# SPC1169 register map
File version: 2022071043481212
CPU: cm4 r1p0, little endian, no MPU, FPU, 4 interrupt priority bits
Registers are 32-bit, read-write, reset 0x0 unless marked. A register's access mark holds for its fields unless they carry their own. Offsets are from the block's base; [hi:lo] are bit positions; {n}, {i} and the like mark numbered series; 'fields as' and 'values as' point back to an identical list.

## ECAP
Base 0x40003400
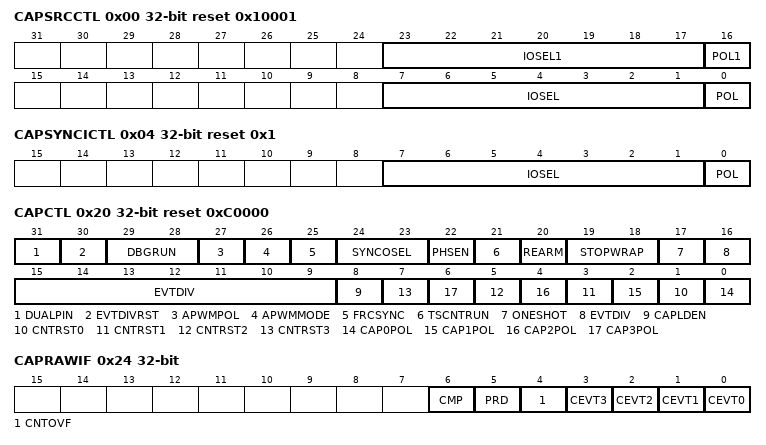
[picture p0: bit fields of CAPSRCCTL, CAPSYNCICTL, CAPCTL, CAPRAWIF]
0x00 CAPSRCCTL reset 0x10001 — Capture Source Input Control Register
  [23:17] IOSEL1 — GPIO number to be selected as 2nd capture input in dual pin mode
  [16] POL1 — Source input polarity for the 2nd pin in dual pin mode
    0=ACTIVE_LOW; 1=ACTIVE_HIGH
  [7:1] IOSEL — GPIO number to be selected as capture input
  [0] POL — Source input polarity
    0=ACTIVE_LOW; 1=ACTIVE_HIGH
0x04 CAPSYNCICTL reset 0x1 — Capture Synchronization Source Input Control Register
  [7:1] IOSEL — GPIO number to be selected as sync input
  [0] POL — Source input polarity
    0=ACTIVE_LOW; 1=ACTIVE_HIGH
0x08 CAPTSCNT — Time-Stamp Counter Register
  [31:0] VAL — Active 32-bit counter register that is used as the capture time-base.
0x0C CAPCNTPHS — Counter Phase Offset Value Register
  [31:0] VAL — Counter phase value register that can be programmed for phase lag/lead.
0x10 CAP0 — Capture Register 0
  [31:0] VAL — In capture mode -This register is loaded from time-stamp counter (CAPTSCNT) upon a capture event 0. . In APWM mode -Writting to this register set the active value of PRD, and also update CAP2 with the same value. This emulates the immediate mode. - Upon CAPTSCNT=PRD (CAP0), this register is updated as CAP2. This emulates the shadow mode.
0x14 CAP1 — Capture Register 1
  [31:0] VAL — In capture mode -This register is loaded from time-stamp counter (CAPTSCNT) upon a capture event 1. . In APWM mode -Writting to this register set the active value of CMP, and also update CAP3 with the same value. This emulates the immediate mode. - Upon CAPTSCNT=PRD (CAP0), this register is updated as CAP3. This emulates the shadow mode.
0x18 CAP2 — Capture Register 2
  [31:0] VAL — In capture mode -This register is loaded from time-stamp counter (CAPTSCNT) upon a capture event 2. . In APWM mode -Writting to this register set the shadow value of PRD. Upon CAPTSCNT=PRD (CAP0), CAP0 will be updated to the value of this register. This emulates the shadow mode.
0x1C CAP3 — Capture Register 3
  [31:0] VAL — In capture mode -This register is loaded from time-stamp counter (CAPTSCNT) upon a capture event 3. . In APWM mode -Writting to this register set the shadow value of CMP. Upon CAPTSCNT=PRD (CAP0), CAP1 will be updated to the value of this register. This emulates the shadow mode.
0x20 CAPCTL reset 0xC0000 — Capture Control Register
  [31] DUALPIN — Dual pin capture mode
    0=DISABLE (CAP0 ~ CAP3 are used for capture the single pin); 1=ENABLE (Use CAP0/CAP2 to capture one pin and CAP1/CAP3 to capture the other)
  [30] EVTDIVRST — Event divider reset
    0=NO_EFFECT (Write 0 has no effect and always reads back 0); 1=RESET (Write 1 resets the event divider. This bit is self-cleared)
  [29:28] DBGRUN — ECAP counter behaviour when CPU is halted. Note: Debug operation and CPU fault exceptions both can cause CPU halted.
    0=STOP_IMMEDIATELY (Counter stops immediately when CPU is halted); 1=STOP_AT_ZERO (Counter runs until 0 when CPU is halted); 2=KEEP_RUNNING (Counter is unaffected when CPU is halted)
  [27] APWMPOL — APWM output polarity select. This is applicable only in APWM operating mode.
    0=ACTIVE_LOW (Output is active low (i.e., CMP defines duration for output low)); 1=ACTIVE_HIGH (Output is active high (i.e., CMP defines duration for output high))
  [26] APWMMODE — CAP/APWM operating mode select
    0=CAPTURE_MODE (ECAP module operates in capture mode. This mode forces the following configuration: - Inhibits counter reset via CNT = PRD event - Inhibits shadow load on CAP0 and CAP1 registers - Permits user to enable CAP0-3 register load - CAPx/APWMx pin operates as a capture input); 1=APWM_MODE (ECAP module operates in APWM mode. This mode forces the following configuration: - Resets counter on CNT = PRD event (period boundary - Permits shadow loading on CAP0 and CAP1 registers - Disables loading of time-stamps into CAP0-3 registers - CAPx/APWMx pin operates as a APWM output)
  [25] FRCSYNC — Software-forced counter synchronizing.
    0=NO_EFFECT (Write 0 has no effect and always reads back 0); 1=FORCE (Write 1 forces a sync event. This bit is self-cleared.)
  [24:23] SYNCOSEL — Sync-Out Select
    1=DISABLE_SYNC_OUT (Disable sync out signal); 2=SYNC_IN (Select sync-in event to be the sync-out signal (pass through)); 3=CNT_EQU_PRD (Select CNT = PRD event to be the sync-out signal)
  [22] PHSEN — Phase synchronization enable
    0=DISABLE (Disable synchronization); 1=ENABLE (Enable counter (CAPTSCNT) to be loaded from CAPCNTPHS register upon either a SYNCI signal or a S/W force event)
  [21] TSCNTRUN — Time stamp counter run/stop control
    0=STOP_COUNTER (Stop counting); 1=START_COUNTER (Free running)
  [20] REARM — One-shot re-arming control.
    0=NO_EFFECT (Write 0 has no effect and always reads back 0); 1=FORCE (Write 1 forces events below. This bit is self-cleared. - Resets the MOD4 counter to zero - Unfreezes the MOD4 counter - Enables capture register loads - Reset event prescaler)
  [19:18] STOPWRAP — Stop value for one-shot mode. This is the number (between 0-3) of captures allowed to occur before the CAP(0-3) registers are frozen, i.e., capture sequence is stopped. Wrap value for continuous mode. This is the number (between 0-3) of the capture register in which the circular buffer wraps around and starts again. Notes: Following 2 actions occurs when MOD4=STOPWRAP: - MOD4 counter is stopped (frozen) - Capture register loads are inhibited. In one-shot mode, further interrupt events are blocked until re-armed.
    {v}=ON_CAPTURE_EVENT{v} (Stop after capture event {v} in one-shot mode. Wrap after capture event {v} in continuous mode.) (v=0..3)
  [17] ONESHOT — One-shot mode enable (applicable only in capture mode)
    0=DISABLE (Operate in continuous mode); 1=ENABLE (Operate in one-shot mode)
  [16:9] EVTDIV — Event Filter prescale select
  [8] CAPLDEN — Enable CAP0-3 loading on a capture event. This bit does not affect the generation of CEVT0-3 events
    0=DISABLE; 1=ENABLE
  [2n+1] CNTRST{n} (n=0..3) — Counter reset on capture event {n}
    0=DISABLE (Do not reset counter); 1=ENABLE (Reset counter)
  [2n] CAP{n}POL (n=0..3) — Capture event {n} polarity select
    0=TRIG_ON_FALLING_EDGE (Triggered on a falling edge); 1=TRIG_ON_RISING_EDGE (Triggered on a rising edge)
0x24 CAPRAWIF ro — Capture Interrupt Raw Flag Register
  [all] fields
    0=NOT_OCCUR (Event did not occur); 1=OCCUR (Event occurred)
  [6] CMP — CAPTSCNT=CAP1 (CMP) event raw flag. This flag is active only in APWM mode.
  [5] PRD — CAPTSCNT=CAP0 (PRD) event raw flag. This flag is only active in APWM mode.
  [4] CNTOVF — Counter overflow (CAPTSCNT=0xFFFFFFFF) event raw flag. This flag is active in CAP and APWM mode.
  [3] CEVT3 — Capture event 3 raw flag. This flag is only active in CAP mode.
  [2] CEVT2 — Capture event 2 raw flag. This flag is active only in CAP mode.
  [1] CEVT1 — Capture event 1 raw flag. This flag is only active in CAP mode.
  [0] CEVT0 — Capture event 0 raw flag. This flag is only active in CAP mode.
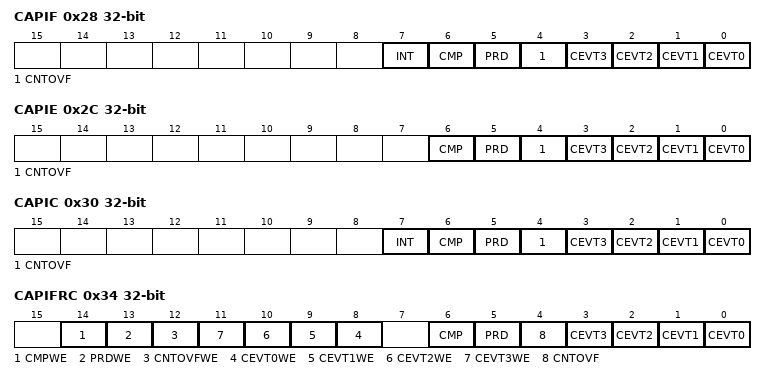
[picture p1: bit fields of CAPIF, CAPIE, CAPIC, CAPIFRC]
0x28 CAPIF ro — Capture Interrupt Flag Register
  [7] INT — Global interrupt flag
    0=NOT_OCCUR (Interrupt is not triggerred); 1=OCCUR (Interrupt is triggered and issued to the CPU. Further interrupt pulse to the CPU will not be generated until this bit is cleared.)
  [6] CMP — CAPTSCNT=CAP1 (CMP) event interrupt flag. This flag is active only in APWM mode.
    0=NOT_OCCUR (Interrupt is not triggerred.); 1=OCCUR (Interrupt is triggerred. Further event will not trigger interrupt until this bit is cleared.)
  [5] PRD — CAPTSCNT=CAP0 (PRD) event interrupt flag. This flag is only active in APWM mode.
    values as CMP
  [4] CNTOVF — Counter overflow (CAPTSCNT=0xFFFFFFFF) event interrupt flag. This flag is active in CAP and APWM mode.
    values as CMP
  [3] CEVT3 — Capture event 3 interrupt flag. This flag is only active in CAP mode.
    values as CMP
  [2] CEVT2 — Capture event 2 interrupt flag. This flag is active only in CAP mode.
    values as CMP
  [1] CEVT1 — Capture event 1 interrupt flag. This flag is only active in CAP mode.
    values as CMP
  [0] CEVT0 — Capture event 0 interrupt flag. This flag is only active in CAP mode.
    values as CMP
0x2C CAPIE — Capture Interrupt Enable Register
  [all] fields
    0=DISABLE; 1=ENABLE
  [6] CMP — CAPTSCNT=CAP1 (CMP) interrupt enable
  [5] PRD — CAPTSCNT=CAP0 (PRD) interrupt enable
  [4] CNTOVF — Counter overflow interrupt enable
  [n] CEVT{n} (n=0..3) — Capture event {n} interrupt enable
0x30 CAPIC — Capture Interrupt Clear Register
  [all] fields
    0=NO_EFFECT (Write 0 has no effect and always reads back 0); 1=CLEAR (Write 1 clears the flag. This bit is self cleared.)
  [7] INT — Global interrupt clear
  [6] CMP — CAPTSCNT=CAP1 (CMP) interrupt clear
  [5] PRD — CAPTSCNT=CAP0 (PRD) interrupt clear
  [4] CNTOVF — Counter overflow interrupt clear
  [n] CEVT{n} (n=0..3) — Capture event {n} interrupt clear
0x34 CAPIFRC — Capture Interrupt Event Force Register
  [14] CMPWE — CMP bit write enable
    0=DISABLE; 1=ENABLE
  [13] PRDWE — PRD bit write enable
    0=DISABLE; 1=ENABLE
  [12] CNTOVFWE — CNTOVF bit write enable
    0=DISABLE; 1=ENABLE
  [n+8] CEVT{n}WE (n=0..3) — CEVT{n} bit write enable
    0=DISABLE; 1=ENABLE
  [6] CMP — CAPTSCNT=CAP1 (CMP) event force.
    0=NO_EFFECT (Write 0 has no effect and always reads back 0); 1=FORCE (Write 1 forces an event. This bit is self-cleared.)
  [5] PRD — CAPTSCNT=CAP0 (PRD) event force.
    values as CMP
  [4] CNTOVF — Counter overflow event force
    values as CMP
  [n] CEVT{n} (n=0..3) — Capture event {n} force
    values as CMP
0x38 CAPREGKEY reset 0x1ACCE551 — Capture Register Write-Allow Key Register
  [31:0] KEY — Write 0x1ACCE551 to unlock protected capture registers
